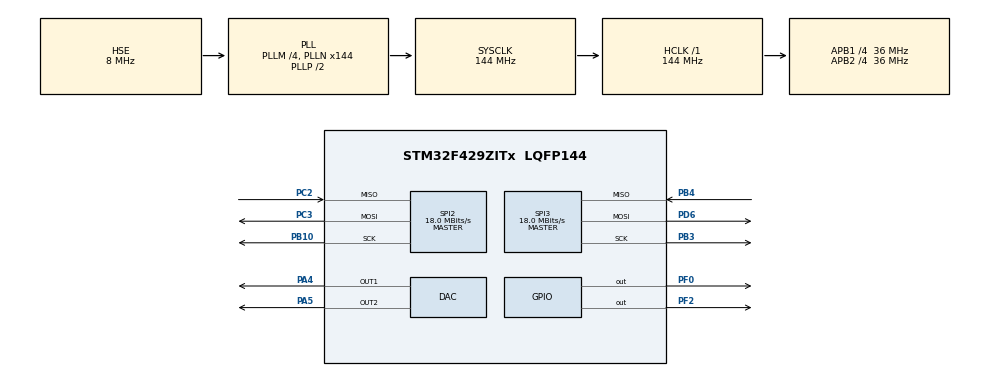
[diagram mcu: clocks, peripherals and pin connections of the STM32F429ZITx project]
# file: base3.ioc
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DAC.DAC_Trigger=DAC_TRIGGER_T6_TRGO
DAC.DAC_Trigger2=DAC_TRIGGER_T6_TRGO
Dma.DAC1.0.Direction=DMA_MEMORY_TO_PERIPH
Dma.DAC1.0.FIFOMode=DMA_FIFOMODE_DISABLE
Dma.DAC1.0.Instance=DMA1_Stream5
Dma.DAC1.0.MemDataAlignment=DMA_MDATAALIGN_HALFWORD
Dma.DAC1.0.MemInc=DMA_MINC_ENABLE
Dma.DAC1.0.Mode=DMA_NORMAL
Dma.DAC1.0.PeriphDataAlignment=DMA_PDATAALIGN_HALFWORD
Dma.DAC1.0.PeriphInc=DMA_PINC_DISABLE
Dma.DAC1.0.Priority=DMA_PRIORITY_HIGH
Dma.DAC2.1.Direction=DMA_MEMORY_TO_PERIPH
Dma.DAC2.1.FIFOMode=DMA_FIFOMODE_DISABLE
Dma.DAC2.1.Instance=DMA1_Stream6
Dma.DAC2.1.MemDataAlignment=DMA_MDATAALIGN_HALFWORD
Dma.DAC2.1.MemInc=DMA_MINC_ENABLE
Dma.DAC2.1.Mode=DMA_NORMAL
Dma.DAC2.1.PeriphDataAlignment=DMA_PDATAALIGN_HALFWORD
Dma.DAC2.1.PeriphInc=DMA_PINC_DISABLE
Dma.DAC2.1.Priority=DMA_PRIORITY_HIGH
Dma.Request0=DAC1
Dma.Request1=DAC2
Mcu.Family=STM32F4
Mcu.Name=STM32F429ZITx
Mcu.Package=LQFP144
NVIC.DMA1_Stream5_IRQn=true\:0\:0\:false\:false\:true\:false
NVIC.DMA1_Stream6_IRQn=true\:0\:0\:false\:false\:true\:false
NVIC.PriorityGroup=NVIC_PRIORITYGROUP_0
NVIC.TIM6_DAC_IRQn=true\:0\:0\:false\:false\:true\:true
PA4.Signal=COMP_DAC1_group
PA5.Signal=COMP_DAC2_group
PB10.Mode=Full_Duplex_Master
PB10.Signal=SPI2_SCK
PB3.Mode=Full_Duplex_Master
PB3.Signal=SPI3_SCK
PB4.Mode=Full_Duplex_Master
PB4.Signal=SPI3_MISO
PC2.Mode=Full_Duplex_Master
PC2.Signal=SPI2_MISO
PC3.Mode=Full_Duplex_Master
PC3.Signal=SPI2_MOSI
PD6.Mode=Full_Duplex_Master
PD6.Signal=SPI3_MOSI
PF0.Signal=GPIO_Output
PF2.Signal=GPIO_Output
PH0/OSC_IN.Mode=HSE-External-Oscillator
PH0/OSC_IN.Signal=RCC_OSC_IN
PH1/OSC_OUT.Mode=HSE-External-Oscillator
PH1/OSC_OUT.Signal=RCC_OSC_OUT
ProjectManager.HeapSize=0x2000
ProjectManager.StackSize=0x4000
ProjectManager.TargetToolchain=SW4STM32
RCC.48MHZClocksFreq_Value=48000000
RCC.AHBFreq_Value=144000000
RCC.APB1CLKDivider=RCC_HCLK_DIV4
RCC.APB1Freq_Value=36000000
RCC.APB1TimFreq_Value=72000000
RCC.APB2CLKDivider=RCC_HCLK_DIV4
RCC.APB2Freq_Value=36000000
RCC.APB2TimFreq_Value=72000000
RCC.CortexFreq_Value=144000000
RCC.HCLKFreq_Value=144000000
RCC.HSE_VALUE=8000000
RCC.HSI_VALUE=16000000
RCC.LSE_VALUE=32768
RCC.PLLM=4
RCC.PLLN=144
RCC.PLLQ=6
RCC.PLLSourceVirtual=RCC_PLLSOURCE_HSE
RCC.SYSCLKFreq_VALUE=144000000
RCC.SYSCLKSource=RCC_SYSCLKSOURCE_PLLCLK
RCC.VCOOutputFreq_Value=288000000
SH.COMP_DAC1_group.0=DAC_OUT1,DAC_OUT1
SH.COMP_DAC2_group.0=DAC_OUT2,DAC_OUT2
SPI2.BaudRatePrescaler=SPI_BAUDRATEPRESCALER_2
SPI2.CalculateBaudRate=18.0 MBits/s
SPI2.Direction=SPI_DIRECTION_2LINES
SPI2.Mode=SPI_MODE_MASTER
SPI2.VirtualType=VM_MASTER
SPI3.BaudRatePrescaler=SPI_BAUDRATEPRESCALER_2
SPI3.CalculateBaudRate=18.0 MBits/s
SPI3.Direction=SPI_DIRECTION_2LINES
SPI3.Mode=SPI_MODE_MASTER
SPI3.VirtualType=VM_MASTER
TIM6.TIM_MasterOutputTrigger=TIM_TRGO_UPDATE
VP_FATFS_VS_Generic.Mode=User_defined
VP_TIM12_VS_ClockSourceINT.Mode=Internal
VP_TIM3_VS_ClockSourceINT.Mode=Internal
VP_TIM4_VS_ClockSourceINT.Mode=Internal
VP_TIM5_VS_ClockSourceINT.Mode=Internal
VP_TIM6_VS_ClockSourceINT.Mode=Enable_Timer
VP_TIM7_VS_ClockSourceINT.Mode=Enable_Timer
VP_TIM8_VS_ClockSourceINT.Mode=Internal
VP_TIM9_VS_ClockSourceINT.Mode=Internal
board=32F429IDISCOVERY

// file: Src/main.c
/**
  ******************************************************************************
  * @file           : main.c
  * @brief          : Main program body
  ******************************************************************************
  * This notice applies to any and all portions of this file
  * that are not between comment pairs USER CODE BEGIN and
  * USER CODE END. Other portions of this file, whether
  * inserted by the user or by software development tools
  * are owned by their respective copyright owners.
  *
  * Copyright (c) 2018 STMicroelectronics International N.V.
  * All rights reserved.
  *
  * Redistribution and use in source and binary forms, with or without
  * modification, are permitted, provided that the following conditions are met:
  *
  * 1. Redistribution of source code must retain the above copyright notice,
  *    this list of conditions and the following disclaimer.
  * 2. Redistributions in binary form must reproduce the above copyright notice,
  *    this list of conditions and the following disclaimer in the documentation
  *    and/or other materials provided with the distribution.
  * 3. Neither the name of STMicroelectronics nor the names of other
  *    contributors to this software may be used to endorse or promote products
  *    derived from this software without specific written permission.
  * 4. This software, including modifications and/or derivative works of this
  *    software, must execute solely and exclusively on microcontroller or
  *    microprocessor devices manufactured by or for STMicroelectronics.
  * 5. Redistribution and use of this software other than as permitted under
  *    this license is void and will automatically terminate your rights under
  *    this license.
  *
  * THIS SOFTWARE IS PROVIDED BY STMICROELECTRONICS AND CONTRIBUTORS "AS IS"
  * AND ANY EXPRESS, IMPLIED OR STATUTORY WARRANTIES, INCLUDING, BUT NOT
  * LIMITED TO, THE IMPLIED WARRANTIES OF MERCHANTABILITY, FITNESS FOR A
  * PARTICULAR PURPOSE AND NON-INFRINGEMENT OF THIRD PARTY INTELLECTUAL PROPERTY
  * RIGHTS ARE DISCLAIMED TO THE FULLEST EXTENT PERMITTED BY LAW. IN NO EVENT
  * SHALL STMICROELECTRONICS OR CONTRIBUTORS BE LIABLE FOR ANY DIRECT, INDIRECT,
  * INCIDENTAL, SPECIAL, EXEMPLARY, OR CONSEQUENTIAL DAMAGES (INCLUDING, BUT NOT
  * LIMITED TO, PROCUREMENT OF SUBSTITUTE GOODS OR SERVICES; LOSS OF USE, DATA,
  * OR PROFITS; OR BUSINESS INTERRUPTION) HOWEVER CAUSED AND ON ANY THEORY OF
  * LIABILITY, WHETHER IN CONTRACT, STRICT LIABILITY, OR TORT (INCLUDING
  * NEGLIGENCE OR OTHERWISE) ARISING IN ANY WAY OUT OF THE USE OF THIS SOFTWARE,
  * EVEN IF ADVISED OF THE POSSIBILITY OF SUCH DAMAGE.
  *
  ******************************************************************************
  */
#include "main.h"
#include "stm32f4xx_hal.h"
#include "dac.h"
#include "dma.h"
#include "fatfs.h"
#include "spi.h"
#include "tim.h"
#include "gpio.h"

/* USER CODE BEGIN PV */
/* Private variables ---------------------------------------------------------*/
DAC_HandleTypeDef hdac;
TIM_HandleTypeDef htim6;
DMA_HandleTypeDef hdma_dac_ch1;
/* USER CODE END PV */

void SystemClock_Config(void);

/* USER CODE BEGIN PFP */
/* Private function prototypes -----------------------------------------------*/

/* USER CODE END PFP */

int main(void)
{

  /* MCU Configuration----------------------------------------------------------*/

  /* Reset of all peripherals, Initializes the Flash interface and the Systick. */
  HAL_Init();

  /* Configure the system clock */
  SystemClock_Config();

  /* Initialize all configured peripherals */
  MX_GPIO_Init();
  MX_DMA_Init();
  MX_DAC_Init();
  MX_SPI3_Init();
  MX_TIM8_Init();
  MX_TIM9_Init();
  MX_TIM12_Init();
  MX_TIM5_Init();
  MX_TIM4_Init();
  MX_TIM3_Init();
  MX_SPI2_Init();
  MX_FATFS_Init();
  MX_TIM6_Init();
  MX_TIM7_Init();
  /* USER CODE BEGIN 2 */

  FATFS myFATFS;
  FIL myFILE;
  UINT testByte;

  if(f_mount(&myFATFS,"/",1) == FR_OK){
	  HAL_GPIO_WritePin(GPIOF,GPIO_PIN_0,SET);
	  char myPath[] = "WRITE.TXT\0";
	  f_open(&myFILE,myPath, FA_WRITE | FA_CREATE_ALWAYS);
	  char myData[] = "Hello World";
	  f_write(&myFILE, myData, sizeof(myData), &testByte);
	  f_close(&myFILE);
  }

  /* USER CODE END 2 */

  /* Infinite loop */
  while (1)
  {

  }

}

void SystemClock_Config(void)
{

  RCC_OscInitTypeDef RCC_OscInitStruct;
  RCC_ClkInitTypeDef RCC_ClkInitStruct;

    /**Configure the main internal regulator output voltage
    */
  __HAL_RCC_PWR_CLK_ENABLE();

  __HAL_PWR_VOLTAGESCALING_CONFIG(PWR_REGULATOR_VOLTAGE_SCALE1);

    /**Initializes the CPU, AHB and APB busses clocks
    */
  RCC_OscInitStruct.OscillatorType = RCC_OSCILLATORTYPE_HSE;
  RCC_OscInitStruct.HSEState = RCC_HSE_ON;
  RCC_OscInitStruct.PLL.PLLState = RCC_PLL_ON;
  RCC_OscInitStruct.PLL.PLLSource = RCC_PLLSOURCE_HSE;
  RCC_OscInitStruct.PLL.PLLM = 4;
  RCC_OscInitStruct.PLL.PLLN = 144;
  RCC_OscInitStruct.PLL.PLLP = RCC_PLLP_DIV2;
  RCC_OscInitStruct.PLL.PLLQ = 6;
  if (HAL_RCC_OscConfig(&RCC_OscInitStruct) != HAL_OK)
  {
    _Error_Handler(__FILE__, __LINE__);
  }

    /**Initializes the CPU, AHB and APB busses clocks
    */
  RCC_ClkInitStruct.ClockType = RCC_CLOCKTYPE_HCLK|RCC_CLOCKTYPE_SYSCLK
                              |RCC_CLOCKTYPE_PCLK1|RCC_CLOCKTYPE_PCLK2;
  RCC_ClkInitStruct.SYSCLKSource = RCC_SYSCLKSOURCE_PLLCLK;
  RCC_ClkInitStruct.AHBCLKDivider = RCC_SYSCLK_DIV1;
  RCC_ClkInitStruct.APB1CLKDivider = RCC_HCLK_DIV4;
  RCC_ClkInitStruct.APB2CLKDivider = RCC_HCLK_DIV4;

  if (HAL_RCC_ClockConfig(&RCC_ClkInitStruct, FLASH_LATENCY_4) != HAL_OK)
  {
    _Error_Handler(__FILE__, __LINE__);
  }

    /**Configure the Systick interrupt time
    */
  HAL_SYSTICK_Config(HAL_RCC_GetHCLKFreq()/1000);

    /**Configure the Systick
    */
  HAL_SYSTICK_CLKSourceConfig(SYSTICK_CLKSOURCE_HCLK);

  /* SysTick_IRQn interrupt configuration */
  HAL_NVIC_SetPriority(SysTick_IRQn, 0, 0);
}

void _Error_Handler(char *file, int line)
{
  while(1)
  {
  }
}

/************************ (C) COPYRIGHT STMicroelectronics *****END OF FILE****/
